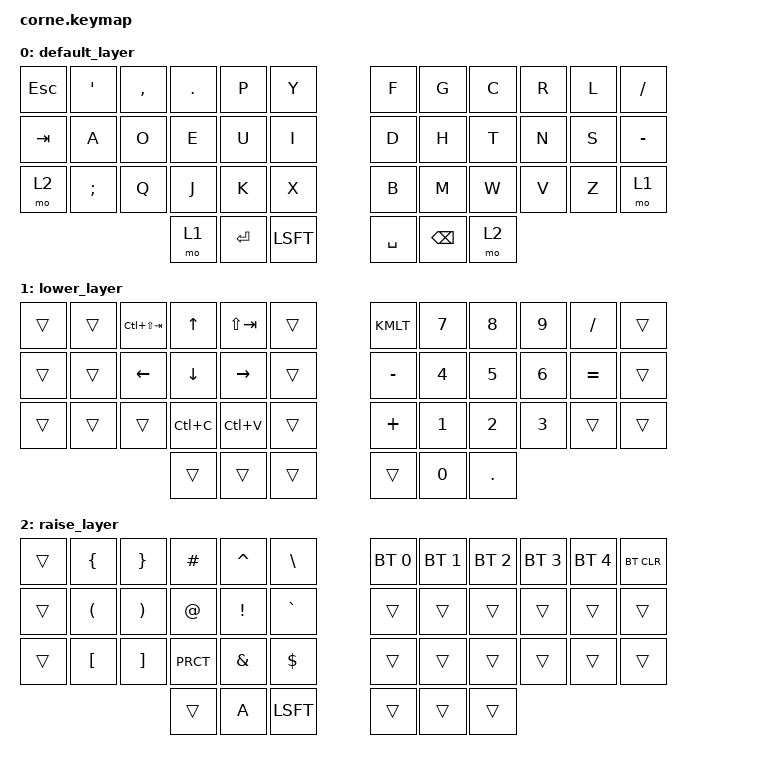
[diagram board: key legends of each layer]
/*
 * Copyright (c) 2020 The ZMK Contributors
 *
 * SPDX-License-Identifier: MIT
 */

#include <behaviors.dtsi>
#include <dt-bindings/zmk/keys.h>
#include <dt-bindings/zmk/bt.h>

/ {
        keymap {
                compatible = "zmk,keymap";

                default_layer {
// -----------------------------------------------------------------------------------------
// | ESC |  '  |  ,  |  .  |  P  |  Y  |   |  F  |  G   |  C  |  R  |  L  | /   |
// | TAB |  A  |  O  |  E  |  U  |  I  |   |  D  |  H   |  T  |  N  |  S  |  -  |
// | MO2 |  ;  |  Q  |  J  |  K  |  X  |   |  B  |  M   |  W  |  V  |  Z  | MO1 | // second copy of MO keys for arrows and bluetooth controls on the opposite hand
//                   | MO1 | RET | SFT |   | SPC | BSPC  | MO2 |
                        bindings = <
   &kp ESC  &kp QUOT &kp CMMA &kp DOT &kp P &kp Y   &kp F &kp G  &kp C &kp R &kp L &kp FSLH
   &kp TAB &kp A &kp O &kp E &kp U &kp I            &kp D &kp H  &kp T &kp N &kp S &kp MINUS
   &mo 2 &kp SCLN &kp Q &kp J &kp K &kp X           &kp B &kp M  &kp W &kp V &kp Z &mo 1
                   &mo 1 &kp RET &kp LSFT           &kp SPC &kp BSPC &mo 2
                        >;
                };
                lower_layer {
// -----------------------------------------------------------------------------------------
// |    |     |BKTAB|  ^  |ONTAB|     |   |  *  |  7  |  8  |  9  |  /  |      |
// |    |     | <-  |  v  |  -> |     |   |  -  |  4  |  5  |  6  |  =  |      |    //maybe swap arrows and bt controls between layers one and two
// |    |     |     |COPY |PASTE|     |   |  +  |  1  |  2  |  3  |     |      |
//                  |     |     |     |   |     |  0  |  .  |
                        bindings = <
   &trans &trans &kp LC(LS(TAB)) &kp UP   &kp LS(TAB) &trans       &kp KMLT  &kp NUM_7 &kp NUM_8 &kp NUM_9 &kp FSLH  &trans
   &trans &trans &kp LEFT &kp DOWN &kp RIGHT  &trans       &kp MINUS &kp NUM_4 &kp NUM_5 &kp NUM_6 &kp EQUAL &trans
   &trans &trans &trans   &kp LC(C)&kp LC(V)  &trans       &kp PLUS  &kp NUM_1 &kp NUM_2 &kp NUM_3 &trans    &trans
                          &trans   &trans      &trans       &trans    &kp NUM_0 &kp DOT
                        >;
                };

                raise_layer {
// -----------------------------------------------------------------------------------------
// |      |  {  |  }  |  #  |  ^  |  \  |   | BT1 | BT2 | BT3 | BT4 | BT5 | BTC | //connect+pair, 5 devices
// |      |  (  |  )  |  @  |  !  |  `  |   |     |     |     |     |     |     |
// |      |  [  |  ]  |  %  |  &  |  $  |   |     |     |     |     |     |     | // TODO: Fix this row when &mkp is committed
//                    |     |     | SFT |   |     |     |     |
                        bindings = <
   &trans &kp LBRC &kp RBRC &kp HASH &kp CARET &kp BSLH     &bt BT_SEL 0  &bt BT_SEL 1 &bt BT_SEL 2 &bt BT_SEL 3 &bt BT_SEL 4 &bt BT_CLR
   &trans &kp LPRN &kp RPRN &kp AT   &kp EXCL  &kp GRAV     &trans &trans &trans &trans &trans &trans
   &trans &kp LBKT &kp RBKT &kp PRCT &kp AMPS  &kp DLLR     &trans &trans &trans &trans &trans &trans
                                 &trans &kp A &kp LSFT     &trans &trans &trans
                        >;
                };
        };
};

